# CY8C5888LTI_LP097 register map
File version: 0.1
Registers are 8-bit, read-write, no defined reset value unless marked. A register's access mark holds for its fields unless they carry their own. Offsets are from the block's base; [hi:lo] are bit positions; 'fields as' and 'values as' point back to an identical list.

## ADH_Reg
Base 0x00000000
0x40006567 ADH_Reg_STATUS_REG
0x40006587 ADH_Reg_MASK_REG
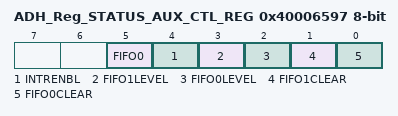
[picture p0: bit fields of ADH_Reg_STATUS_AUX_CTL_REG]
0x40006597 ADH_Reg_STATUS_AUX_CTL_REG
  [5] FIFO0 — FIFO0 clear
    1=ENABLED (Enable counter); 0=DISABLED (Disable counter)
  [4] INTRENBL — Enables or disables the Interrupt
    1=ENABLED (Interrupt enabled); 0=DISABLED (Interrupt disabled)
  [3] FIFO1LEVEL — FIFO level
    1=ENABLED (FIFO LVL: input mode: FIFO at least 1/2 empty; output mode: FIFO at least 1/2 full); 0=DISABLED (FIFO LVL: input mode: FIFO not full; output mode: FIFO not empty)
  [2] FIFO0LEVEL — FIFO level
    values as FIFO1LEVEL
  [1] FIFO1CLEAR — FIFO clear
    1=ENABLED (Clear FIFO state); 0=DISABLED (Normal FIFO operation)
  [0] FIFO0CLEAR — FIFO clear
    values as FIFO1CLEAR

## UART
Base 0x00000000
0x40006428 RX_UART_RX_ADDRESS1 — RX Address1 Register
0x40006438 RX_UART_RX_ADDRESS2 — RX Address2 Register
0x40006447 TX_UART_TX_DATA — TX Data Register
0x40006448 RX_UART_RX_DATA — RX Data Register
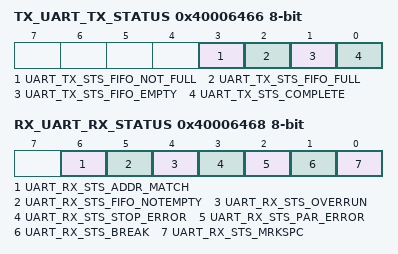
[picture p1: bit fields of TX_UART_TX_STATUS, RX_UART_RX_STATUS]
0x40006466 TX_UART_TX_STATUS — TX status register
  [3] UART_TX_STS_FIFO_NOT_FULL ro, [2] UART_TX_STS_FIFO_FULL ro, [1] UART_TX_STS_FIFO_EMPTY ro, [0] UART_TX_STS_COMPLETE ro
0x40006468 RX_UART_RX_STATUS — RX status register
  [6] UART_RX_STS_ADDR_MATCH ro, [5] UART_RX_STS_FIFO_NOTEMPTY ro, [4] UART_RX_STS_OVERRUN ro, [3] UART_RX_STS_STOP_ERROR ro, [2] UART_RX_STS_PAR_ERROR ro, [1] UART_RX_STS_BREAK ro, [0] UART_RX_STS_MRKSPC ro

## RCM
Base 0x00000000
0x4000646B RCM_STATUS_REG
0x4000648B RCM_MASK_REG
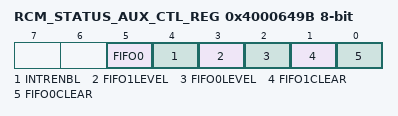
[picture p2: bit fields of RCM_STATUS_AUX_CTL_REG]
0x4000649B RCM_STATUS_AUX_CTL_REG
  [5] FIFO0 — FIFO0 clear
    1=ENABLED (Enable counter); 0=DISABLED (Disable counter)
  [4] INTRENBL — Enables or disables the Interrupt
    1=ENABLED (Interrupt enabled); 0=DISABLED (Interrupt disabled)
  [3] FIFO1LEVEL — FIFO level
    1=ENABLED (FIFO LVL: input mode: FIFO at least 1/2 empty; output mode: FIFO at least 1/2 full); 0=DISABLED (FIFO LVL: input mode: FIFO not full; output mode: FIFO not empty)
  [2] FIFO0LEVEL — FIFO level
    values as FIFO1LEVEL
  [1] FIFO1CLEAR — FIFO clear
    1=ENABLED (Clear FIFO state); 0=DISABLED (Normal FIFO operation)
  [0] FIFO0CLEAR — FIFO clear
    values as FIFO1CLEAR

## SRAM_Ctl
Base 0x00000000
0x40006475 SRAM_Ctl_CONTROL_REG

## RSU
Base 0x00000000
0x40006470 RSU_CONTROL_REG

## RSM
Base 0x00000000
0x40006471 RSM_CONTROL_REG

## Millis
Base 0x00000000
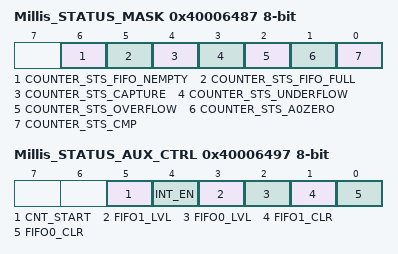
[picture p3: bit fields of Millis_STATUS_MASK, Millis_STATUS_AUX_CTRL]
0x40006487 Millis_STATUS_MASK — UDB Status bits Interrupt Mask Enable Register
  [6] COUNTER_STS_FIFO_NEMPTY — FIFO Not Empty Status
  [5] COUNTER_STS_FIFO_FULL — FIFO Full Status
  [4] COUNTER_STS_CAPTURE — Capture Status
  [3] COUNTER_STS_UNDERFLOW — Underflow status
  [2] COUNTER_STS_OVERFLOW — Overflow status
  [1] COUNTER_STS_A0ZERO — A0 Zero ouput status
  [0] COUNTER_STS_CMP — Compare output status
0x40006497 Millis_STATUS_AUX_CTRL — UDB Auxilliary Control Register
  [5] CNT_START — FIFO0 clear
    0=E_CNT_START0 (Disable counter); 1=E_CNT_START1 (Enable counter)
  [4] INT_EN
    0=E_INT_EN0 (Interrupt disabled); 1=E_INT_EN1 (Interrupt enabled)
  [3] FIFO1_LVL — FIFO level
    0=E_FIFO_LVL_0 (FIFO LVL: input mode: FIFO not full; output mode: FIFO not empty); 1=E_FIFO_LVL_1 (FIFO LVL: input mode: FIFO at least 1/2 empty; output mode: FIFO at least 1/2 full)
  [2] FIFO0_LVL — FIFO level
    values as FIFO1_LVL
  [1] FIFO1_CLR — FIFO1 clear
    0=E_FIFO_CLR_0 (Normal FIFO operation); 1=E_FIFO_CLR_1 (Clear FIFO state)
  [0] FIFO0_CLR — FIFO0 clear
    values as FIFO1_CLR
0x40006504 Millis_COUNTER 32-bit — UDB.A0 - Current Counter Value
0x40006524 Millis_PERIOD 32-bit — UDB.D0 - Assigned Period
0x40006534 Millis_COMPARE 32-bit — UDB.D1 - Assigned Compare Value
